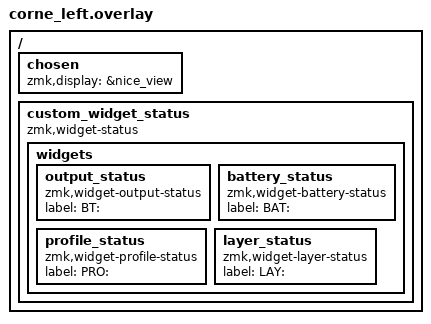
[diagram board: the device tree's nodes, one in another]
#include <dt-bindings/zmk/matrix_transform.h>

/ {
    chosen {
        zmk,display = &nice_view;
    };

    custom_widget_status {
        compatible = "zmk,widget-status";
        
        // Left side widgets
        widgets {
            output_status {
                compatible = "zmk,widget-output-status";
                label = "BT:";
            };
            
            battery_status {
                compatible = "zmk,widget-battery-status"; 
                label = "BAT:";
            };
            
            profile_status {
                compatible = "zmk,widget-profile-status";
                label = "PRO:";
            };
            
            layer_status {
                compatible = "zmk,widget-layer-status";
                label = "LAY:";
            };
        };
    };
};
